# PCIE1_CORE_ECC_AGGR0 register map
Vendor: Texas Instruments
Peripheral module from a debugger description file (folder J721S2).
Registers are 32-bit, access not given, reset 0x0 unless marked. A register's access mark holds for its fields unless they carry their own. Offsets are as the file gives them; lines under a group give offsets from that group; [hi:lo] are bit positions; {n}, {i} and the like mark numbered series; 'fields as' and 'values as' point back to an identical list; <NAME> marks a mode.

## PCIE1_CORE_ECC_AGGR0
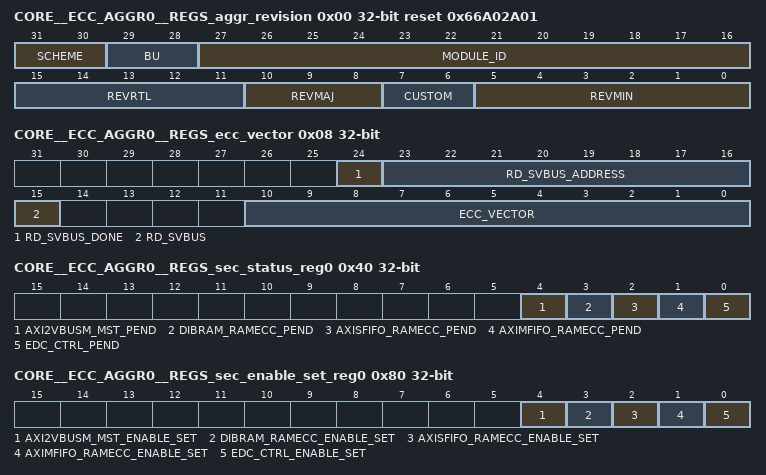
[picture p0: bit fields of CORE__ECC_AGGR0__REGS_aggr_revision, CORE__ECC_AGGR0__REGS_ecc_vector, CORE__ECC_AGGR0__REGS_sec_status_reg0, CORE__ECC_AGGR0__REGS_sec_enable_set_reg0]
0x00 CORE__ECC_AGGR0__REGS_aggr_revision ro reset 0x66A02A01 — Revision parameters
  [31:30] SCHEME
  [29:28] BU
  [27:16] MODULE_ID
  [15:11] REVRTL — RTL version
  [10:8] REVMAJ — Major version
  [7:6] CUSTOM — Custom version
  [5:0] REVMIN — Minor version
0x08 CORE__ECC_AGGR0__REGS_ecc_vector — ECC Vector Register
  [24] RD_SVBUS_DONE — Status to indicate if read on serial VBUS is complete, write of any value will clear this bit. (access R/W1TC)
  [23:16] RD_SVBUS_ADDRESS rw — Read address
  [15] RD_SVBUS — Write 1 to trigger a read on the serial VBUS (access R/W1TS)
  [10:0] ECC_VECTOR rw — Value written to select the corresponding ECC RAM for control or status
0x0C CORE__ECC_AGGR0__REGS_misc_status ro reset 0x5 — Misc Status
  [10:0] NUM_RAMS — Indicates the number of RAMS serviced by the ECC aggregator
0x10 CORE__ECC_AGGR0__REGS_reserved_svbus rw — Reference other documents that contain the ECC RAM wrapper and EDC controller serial vbus register sets.
  [31:0] DATA — Serial VBUS register data
0x3C CORE__ECC_AGGR0__REGS_sec_eoi_reg — EOI Register
  [0] EOI_WR — EOI Register (access R/W1TS)
0x40 CORE__ECC_AGGR0__REGS_sec_status_reg0 — Interrupt Status Register 0
  [4] AXI2VBUSM_MST_PEND — Interrupt Pending Status for axi2vbusm_mst_pend (access R/W1TS)
  [3] DIBRAM_RAMECC_PEND — Interrupt Pending Status for dibram_ramecc_pend (access R/W1TS)
  [2] AXISFIFO_RAMECC_PEND — Interrupt Pending Status for axisfifo_ramecc_pend (access R/W1TS)
  [1] AXIMFIFO_RAMECC_PEND — Interrupt Pending Status for aximfifo_ramecc_pend (access R/W1TS)
  [0] EDC_CTRL_PEND — Interrupt Pending Status for edc_ctrl_pend (access R/W1TS)
0x80 CORE__ECC_AGGR0__REGS_sec_enable_set_reg0 — Interrupt Enable Set Register 0
  [4] AXI2VBUSM_MST_ENABLE_SET — Interrupt Enable Set Register for axi2vbusm_mst_pend (access R/W1TS)
  [3] DIBRAM_RAMECC_ENABLE_SET — Interrupt Enable Set Register for dibram_ramecc_pend (access R/W1TS)
  [2] AXISFIFO_RAMECC_ENABLE_SET — Interrupt Enable Set Register for axisfifo_ramecc_pend (access R/W1TS)
  [1] AXIMFIFO_RAMECC_ENABLE_SET — Interrupt Enable Set Register for aximfifo_ramecc_pend (access R/W1TS)
  [0] EDC_CTRL_ENABLE_SET — Interrupt Enable Set Register for edc_ctrl_pend (access R/W1TS)
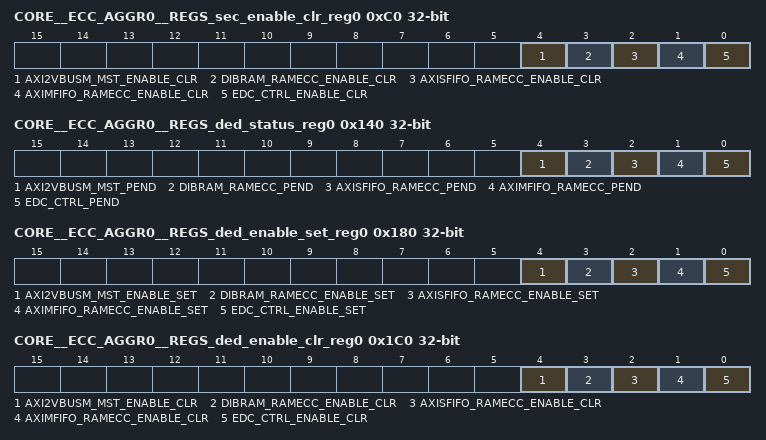
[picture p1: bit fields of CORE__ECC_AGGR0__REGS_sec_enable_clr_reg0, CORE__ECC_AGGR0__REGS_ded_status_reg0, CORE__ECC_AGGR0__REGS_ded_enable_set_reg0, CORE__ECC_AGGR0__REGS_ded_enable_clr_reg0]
0xC0 CORE__ECC_AGGR0__REGS_sec_enable_clr_reg0 — Interrupt Enable Clear Register 0
  [4] AXI2VBUSM_MST_ENABLE_CLR — Interrupt Enable Clear Register for axi2vbusm_mst_pend (access R/W1TC)
  [3] DIBRAM_RAMECC_ENABLE_CLR — Interrupt Enable Clear Register for dibram_ramecc_pend (access R/W1TC)
  [2] AXISFIFO_RAMECC_ENABLE_CLR — Interrupt Enable Clear Register for axisfifo_ramecc_pend (access R/W1TC)
  [1] AXIMFIFO_RAMECC_ENABLE_CLR — Interrupt Enable Clear Register for aximfifo_ramecc_pend (access R/W1TC)
  [0] EDC_CTRL_ENABLE_CLR — Interrupt Enable Clear Register for edc_ctrl_pend (access R/W1TC)
0x13C CORE__ECC_AGGR0__REGS_ded_eoi_reg — EOI Register
  [0] EOI_WR — EOI Register (access R/W1TS)
0x140 CORE__ECC_AGGR0__REGS_ded_status_reg0 — Interrupt Status Register 0
  fields as CORE__ECC_AGGR0__REGS_sec_status_reg0
0x180 CORE__ECC_AGGR0__REGS_ded_enable_set_reg0 — Interrupt Enable Set Register 0
  fields as CORE__ECC_AGGR0__REGS_sec_enable_set_reg0
0x1C0 CORE__ECC_AGGR0__REGS_ded_enable_clr_reg0 — Interrupt Enable Clear Register 0
  fields as CORE__ECC_AGGR0__REGS_sec_enable_clr_reg0
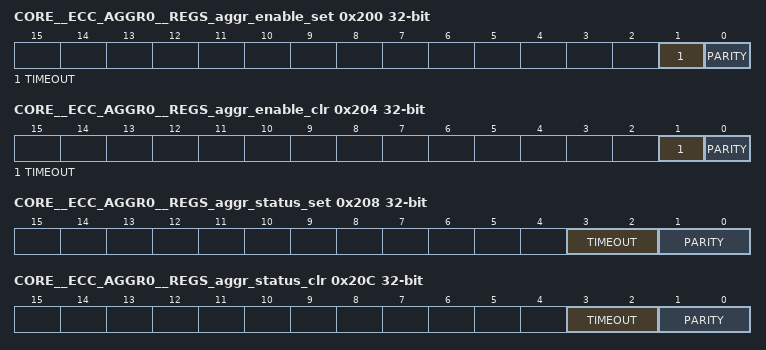
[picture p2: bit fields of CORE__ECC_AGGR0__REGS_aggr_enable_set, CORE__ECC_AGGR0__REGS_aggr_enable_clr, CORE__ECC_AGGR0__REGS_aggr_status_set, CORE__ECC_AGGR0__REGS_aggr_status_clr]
0x200 CORE__ECC_AGGR0__REGS_aggr_enable_set — AGGR interrupt enable set Register
  [1] TIMEOUT — interrupt enable set for svbus timeout errors (access R/W1TS)
  [0] PARITY — interrupt enable set for parity errors (access R/W1TS)
0x204 CORE__ECC_AGGR0__REGS_aggr_enable_clr — AGGR interrupt enable clear Register
  [1] TIMEOUT — interrupt enable clear for svbus timeout errors (access R/W1TC)
  [0] PARITY — interrupt enable clear for parity errors (access R/W1TC)
0x208 CORE__ECC_AGGR0__REGS_aggr_status_set — AGGR interrupt status set Register
  [3:2] TIMEOUT — interrupt status set for svbus timeout errors (access R/WI)
  [1:0] PARITY — interrupt status set for parity errors (access R/WI)
0x20C CORE__ECC_AGGR0__REGS_aggr_status_clr — AGGR interrupt status clear Register
  [3:2] TIMEOUT — interrupt status clear for svbus timeout errors (access R/WD)
  [1:0] PARITY — interrupt status clear for parity errors (access R/WD)
